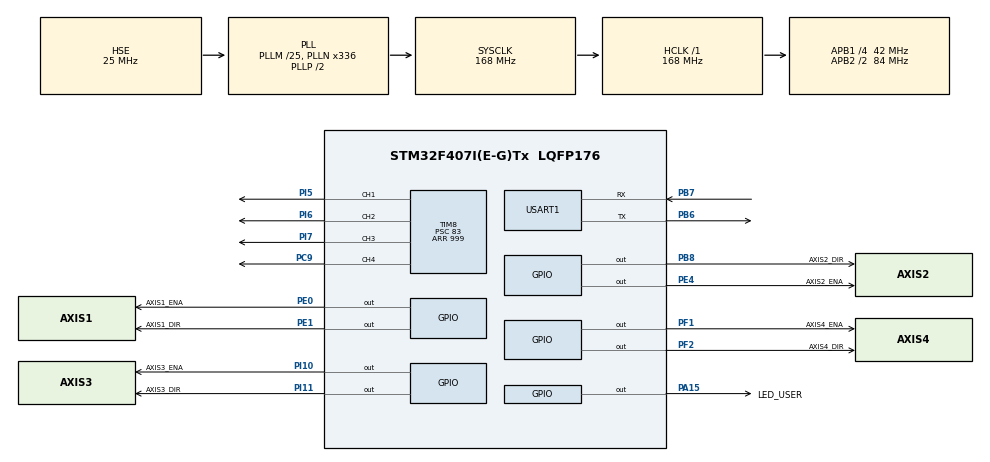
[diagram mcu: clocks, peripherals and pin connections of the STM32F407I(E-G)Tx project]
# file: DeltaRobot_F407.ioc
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Mcu.Family=STM32F4
Mcu.Name=STM32F407I(E-G)Tx
Mcu.Package=LQFP176
NVIC.PriorityGroup=NVIC_PRIORITYGROUP_2
NVIC.TIM2_IRQn=true\:2\:0\:true\:false\:true\:false\:true\:true
NVIC.TimeBase=TIM2_IRQn
NVIC.TimeBaseIP=TIM2
NVIC.USART1_IRQn=true\:3\:0\:true\:false\:true\:true\:true\:true
PA13.Mode=Serial_Wire
PA13.Signal=SYS_JTMS-SWDIO
PA14.Mode=Serial_Wire
PA14.Signal=SYS_JTCK-SWCLK
PA15.GPIO_Label=LED_USER
PA15.GPIO_ModeDefaultOutputPP=GPIO_MODE_OUTPUT_PP
PA15.PinState=GPIO_PIN_SET
PA15.Signal=GPIO_Output
PB6.Mode=Asynchronous
PB6.Signal=USART1_TX
PB7.Mode=Asynchronous
PB7.Signal=USART1_RX
PB8.GPIO_Label=AXIS2_DIR
PB8.GPIO_Speed=GPIO_SPEED_FREQ_HIGH
PB8.Signal=GPIO_Output
PC9.Signal=S_TIM8_CH4
PE0.GPIO_Label=AXIS1_ENA
PE0.GPIO_Speed=GPIO_SPEED_FREQ_HIGH
PE0.PinState=GPIO_PIN_SET
PE0.Signal=GPIO_Output
PE1.GPIO_Label=AXIS1_DIR
PE1.GPIO_Speed=GPIO_SPEED_FREQ_HIGH
PE1.Signal=GPIO_Output
PE4.GPIO_Label=AXIS2_ENA
PE4.GPIO_Speed=GPIO_SPEED_FREQ_HIGH
PE4.PinState=GPIO_PIN_SET
PE4.Signal=GPIO_Output
PF1.GPIO_Label=AXIS4_ENA
PF1.GPIO_Speed=GPIO_SPEED_FREQ_HIGH
PF1.PinState=GPIO_PIN_SET
PF1.Signal=GPIO_Output
PF2.GPIO_Label=AXIS4_DIR
PF2.GPIO_Speed=GPIO_SPEED_FREQ_HIGH
PF2.Signal=GPIO_Output
PH0-OSC_IN.Mode=HSE-External-Oscillator
PH0-OSC_IN.Signal=RCC_OSC_IN
PH1-OSC_OUT.Mode=HSE-External-Oscillator
PH1-OSC_OUT.Signal=RCC_OSC_OUT
PI10.GPIO_Label=AXIS3_ENA
PI10.GPIO_Speed=GPIO_SPEED_FREQ_HIGH
PI10.PinState=GPIO_PIN_SET
PI10.Signal=GPIO_Output
PI11.GPIO_Label=AXIS3_DIR
PI11.GPIO_Speed=GPIO_SPEED_FREQ_HIGH
PI11.Signal=GPIO_Output
PI5.Signal=S_TIM8_CH1
PI6.Signal=S_TIM8_CH2
PI7.Signal=S_TIM8_CH3
ProjectManager.HeapSize=0x200
ProjectManager.StackSize=0x400
ProjectManager.TargetToolchain=MDK-ARM V5.32
RCC.48MHZClocksFreq_Value=84000000
RCC.AHBFreq_Value=168000000
RCC.APB1CLKDivider=RCC_HCLK_DIV4
RCC.APB1Freq_Value=42000000
RCC.APB1TimFreq_Value=84000000
RCC.APB2CLKDivider=RCC_HCLK_DIV2
RCC.APB2Freq_Value=84000000
RCC.APB2TimFreq_Value=168000000
RCC.CortexFreq_Value=168000000
RCC.HCLKFreq_Value=168000000
RCC.HSE_VALUE=25000000
RCC.HSI_VALUE=16000000
RCC.LSE_VALUE=32768
RCC.PLLM=25
RCC.PLLN=336
RCC.PLLSourceVirtual=RCC_PLLSOURCE_HSE
RCC.SYSCLKFreq_VALUE=168000000
RCC.SYSCLKSource=RCC_SYSCLKSOURCE_PLLCLK
RCC.VCOOutputFreq_Value=336000000
SH.S_TIM8_CH1.0=TIM8_CH1,Output Compare1 CH1
SH.S_TIM8_CH2.0=TIM8_CH2,Output Compare2 CH2
SH.S_TIM8_CH3.0=TIM8_CH3,Output Compare3 CH3
SH.S_TIM8_CH4.0=TIM8_CH4,PWM Generation4 CH4
TIM8.AutoReloadPreload=TIM_AUTORELOAD_PRELOAD_ENABLE
TIM8.Channel-Output\ Compare1\ CH1=TIM_CHANNEL_1
TIM8.Channel-Output\ Compare2\ CH2=TIM_CHANNEL_2
TIM8.Channel-Output\ Compare3\ CH3=TIM_CHANNEL_3
TIM8.Channel-PWM\ Generation4\ CH4=TIM_CHANNEL_4
TIM8.Period=999
TIM8.Prescaler=83
TIM8.Pulse-Output\ Compare1\ CH1=499
TIM8.Pulse-Output\ Compare2\ CH2=499
TIM8.Pulse-Output\ Compare3\ CH3=499
USART1.VirtualMode=VM_ASYNC
VP_SYS_VS_tim2.Mode=TIM2
VP_TIM8_VS_ClockSourceINT.Mode=Internal
board=custom

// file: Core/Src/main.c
/* USER CODE BEGIN Header */
/**
  ******************************************************************************
  * @file           : main.c
  * @brief          : Main program body
  ******************************************************************************
  * @attention
  *
  * Copyright (c) 2026 STMicroelectronics.
  * All rights reserved.
  *
  * This software is licensed under terms that can be found in the LICENSE file
  * in the root directory of this software component.
  * If no LICENSE file comes with this software, it is provided AS-IS.
  *
  ******************************************************************************
  */
/* USER CODE END Header */
#include "main.h"
#include "tim.h"
#include "usart.h"
#include "gpio.h"

/* USER CODE BEGIN Includes */
#include <stdio.h>
/* USER CODE END Includes */

/* USER CODE BEGIN PV */

// 串口收发缓冲区
uint8_t aRxBuffer[1];          // 单字节接收缓冲
uint8_t aTxBuffer[] = "Delta Robot Boot OK\r\n";

// 心跳计数
uint32_t aliveCnt = 0;

/* USER CODE END PV */

void SystemClock_Config(void);

int main(void)
{

  /* USER CODE BEGIN 1 */
  /* 此处不能调用 printf：huart1 尚未初始化，HAL_UART_Transmit 首行会因
     gState != HAL_UART_STATE_READY 直接 return HAL_BUSY，静默失败。
     串口打印统一放到 USER CODE 2（外设初始化完成之后）。 */
  /* USER CODE END 1 */

  /* MCU Configuration--------------------------------------------------------*/

  /* Reset of all peripherals, Initializes the Flash interface and the Systick. */
  HAL_Init();

  /* Configure the system clock */
  SystemClock_Config();

  /* Initialize all configured peripherals */
  MX_GPIO_Init();
  MX_TIM8_Init();
  MX_USART1_UART_Init();
  /* USER CODE BEGIN 2 */
  // 发送启动信息（此处 huart1 已初始化完成，printf 与 HAL_UART_Transmit 均可正常使用）
  printf("Delta Robot Init Complete!\r\n");
  HAL_UART_Transmit(&huart1, aTxBuffer, sizeof(aTxBuffer)-1, 1000);

  // 启动串口接收中断（必须！）
  HAL_UART_Receive_IT(&huart1, aRxBuffer, 1);
  /* USER CODE END 2 */

  /* Infinite loop */
  while (1)
  {

    /* USER CODE BEGIN 3 */
    // 每秒一次心跳，用来确认 MCU 侧发送正常（PB6/TX、PB7/RX）
    HAL_GPIO_TogglePin(LED_USER_GPIO_Port, LED_USER_Pin);
    printf("[PB6/PB7] alive %lu\r\n", aliveCnt++);
    HAL_Delay(1000);
  }
  /* USER CODE END 3 */
}

void SystemClock_Config(void)
{
  RCC_OscInitTypeDef RCC_OscInitStruct = {0};
  RCC_ClkInitTypeDef RCC_ClkInitStruct = {0};

  /** Configure the main internal regulator output voltage
  */
  __HAL_RCC_PWR_CLK_ENABLE();
  __HAL_PWR_VOLTAGESCALING_CONFIG(PWR_REGULATOR_VOLTAGE_SCALE1);

  /** Initializes the RCC Oscillators according to the specified parameters
  * in the RCC_OscInitTypeDef structure.
  */
  RCC_OscInitStruct.OscillatorType = RCC_OSCILLATORTYPE_HSE;
  RCC_OscInitStruct.HSEState = RCC_HSE_ON;
  RCC_OscInitStruct.PLL.PLLState = RCC_PLL_ON;
  RCC_OscInitStruct.PLL.PLLSource = RCC_PLLSOURCE_HSE;
  RCC_OscInitStruct.PLL.PLLM = 25;
  RCC_OscInitStruct.PLL.PLLN = 336;
  RCC_OscInitStruct.PLL.PLLP = RCC_PLLP_DIV2;
  RCC_OscInitStruct.PLL.PLLQ = 4;
  if (HAL_RCC_OscConfig(&RCC_OscInitStruct) != HAL_OK)
  {
    Error_Handler();
  }

  /** Initializes the CPU, AHB and APB buses clocks
  */
  RCC_ClkInitStruct.ClockType = RCC_CLOCKTYPE_HCLK|RCC_CLOCKTYPE_SYSCLK
                              |RCC_CLOCKTYPE_PCLK1|RCC_CLOCKTYPE_PCLK2;
  RCC_ClkInitStruct.SYSCLKSource = RCC_SYSCLKSOURCE_PLLCLK;
  RCC_ClkInitStruct.AHBCLKDivider = RCC_SYSCLK_DIV1;
  RCC_ClkInitStruct.APB1CLKDivider = RCC_HCLK_DIV4;
  RCC_ClkInitStruct.APB2CLKDivider = RCC_HCLK_DIV2;

  if (HAL_RCC_ClockConfig(&RCC_ClkInitStruct, FLASH_LATENCY_5) != HAL_OK)
  {
    Error_Handler();
  }
}

/* USER CODE BEGIN 4 */
/**
  * @brief  串口错误回调（帧错误 / 噪声 / 溢出 / DMA 错误）
  * @note   HAL 在发生接收错误时会复位 RxState 并关闭接收中断，
  *         若不在此重新开启接收，回显链路会永久停摆。
  *         该函数在 HAL 中为 __weak 定义，此处重写即可覆盖。
  */
void HAL_UART_ErrorCallback(UART_HandleTypeDef *huart)
{
    if (huart->Instance == USART1)
    {
        HAL_UART_Receive_IT(&huart1, aRxBuffer, 1);
    }
}
/* USER CODE END 4 */

void HAL_TIM_PeriodElapsedCallback(TIM_HandleTypeDef *htim)
{
  if (htim->Instance == TIM2)
  {
    HAL_IncTick();
  }
}

void Error_Handler(void)
{
  __disable_irq();
  while (1)
  {
  }
}
